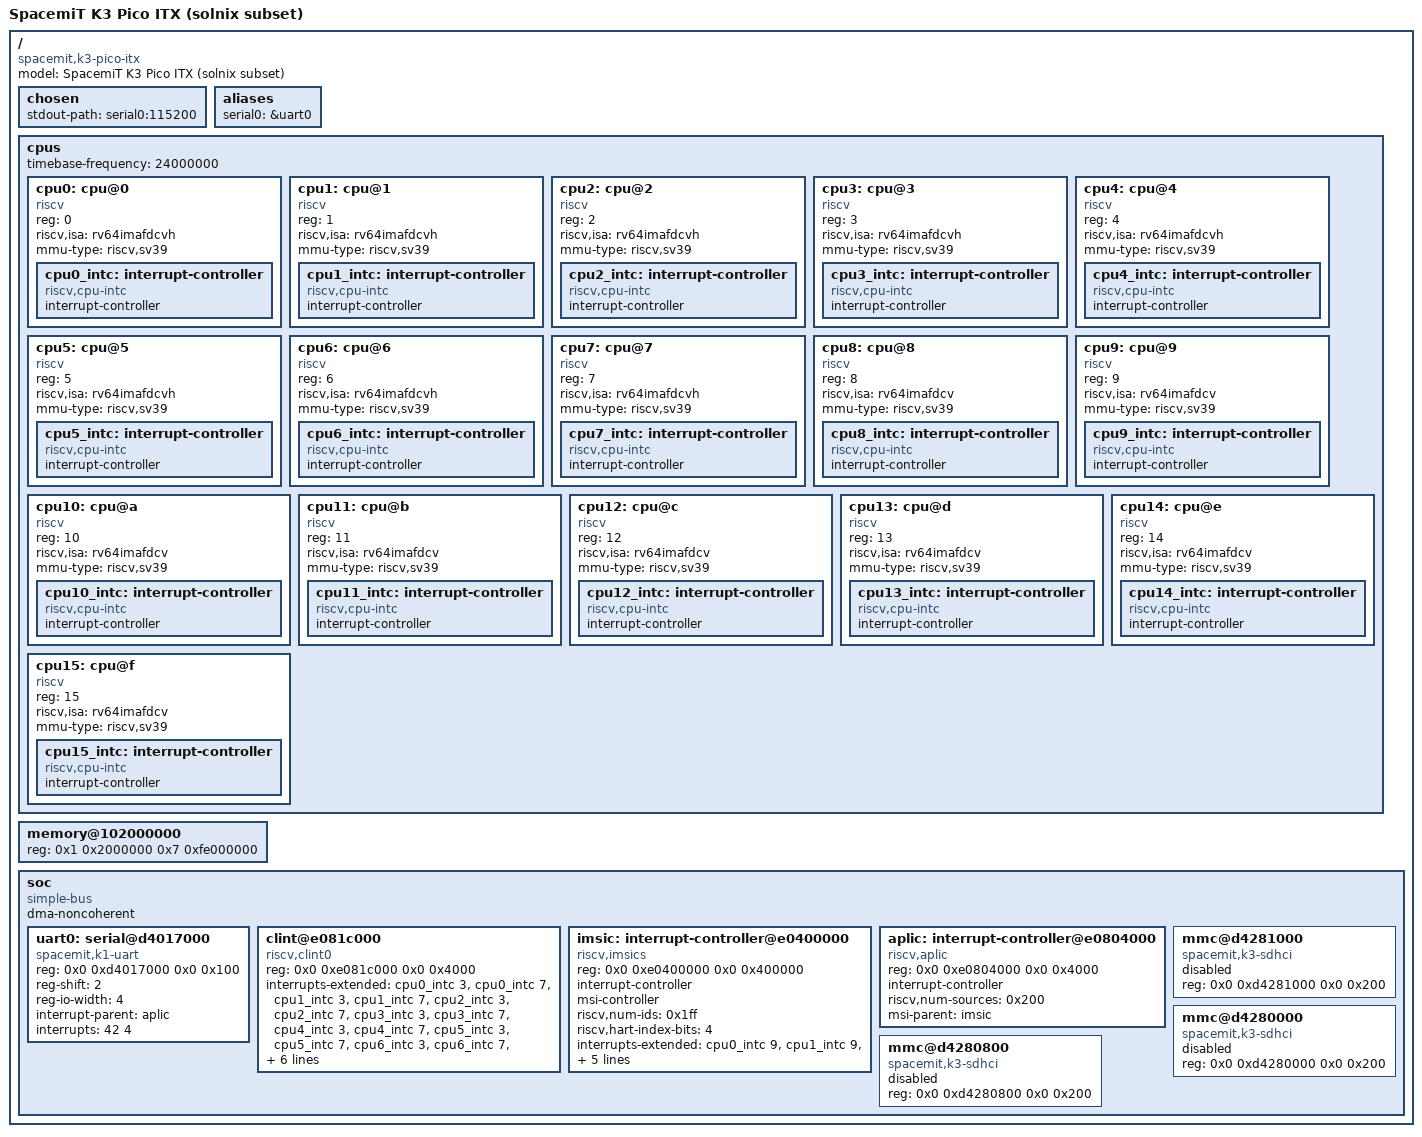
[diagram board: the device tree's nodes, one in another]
/dts-v1/;

/*
 * k3.dts - a faithful SUBSET of the SpacemiT K3 Pico ITX devicetree,
 * GENERATED by gen-k3-dts.py from the board's own vendor DTB dump.
 *
 * DO NOT HAND-EDIT. Re-run:
 *     ./gen-k3-dts.py <vendor.dts> k3.dts
 * Every boot-critical value below was EXTRACTED from the dump, and the
 * generator refuses to emit a file if the dump disagrees with what it
 * expects (16 contiguous sv39 harts, a memory node, an APLIC, and the
 * console UART at 0xd4017000 with reg-shift 2 / reg-io-width 4).
 *
 * The predecessor k1.dts was hand-written before its board existed and was
 * wrong on hart count, interrupt controller, MMC IP and UART bind string.
 * Generating removes exactly that class of error.
 *
 * Source dump : /tmp/dts
 * Board model : SpacemiT K3 Pico ITX
 *
 * MEASURED (from the dump, not inferred):
 *   DRAM         0x102000000 .. 0x900000000  (32.0 GiB)
 *                ^ note this is 32 MiB ABOVE the 4 GiB line,
 *                  so neither 0x80200000 nor a flat 4 GiB is inside DRAM.
 *   timebase     24000000 Hz  (the `time` CSR / CLINT rate)
 *   harts        16: rv64imafdcv x8; rv64imafdcvh x8
 *   console      /soc/serial@d4017000 @ 0xd4017000, serial0:115200
 *                compatible = "spacemit,k1-uart", "intel,xscale-uart"
 *                reg-shift = 2, reg-io-width = 4, IRQ 42
 *   CLINT        0xe081c000 riscv,clint0
 *   APLIC        0xe0804000 riscv,aplic, 512 sources
 *   IMSIC        0xe0400000 riscv,imsics, 511 ids, hart-index-bits 4
 *   SD/MMC       mmc@d4281000 disabled, mmc@d4280000 disabled, mmc@d4280800 disabled
 *                ^ ALL DISABLED on this board. There is no SD card path:
 *                  the boot chain lives in SPI NOR (boot_mode=nor) and the
 *                  root device is UFS. Carried through as disabled so the
 *                  kernel does not bind a controller the board does not use.
 *
 * The K3 is an AIA part (APLIC + IMSIC), so fdt_intc_is_aia() selects
 * uts/aia.c here, NOT the PLIC path uts/plic.c that qemu-virt uses.
 */

/ {
	#address-cells = <2>;
	#size-cells = <2>;
	model = "SpacemiT K3 Pico ITX (solnix subset)";
	compatible = "spacemit,k3-pico-itx";

	chosen {
		stdout-path = "serial0:115200";
	};

	aliases {
		serial0 = &uart0;
	};

	cpus {
		#address-cells = <1>;
		#size-cells = <0>;
		timebase-frequency = <24000000>;	/* measured: 24 MHz */

		/*
		 * 16 harts. SMP bring-up must handle all of them: hart 0
		 * boots and the rest come up via SBI HSM hart_start. The two ISA
		 * strings differ ONLY by the `h` (hypervisor) extension, which we do
		 * not use, and every hart is sv39 -- so this is not a big.LITTLE
		 * problem for the kernel. The COUNT is what matters.
		 */
		cpu0: cpu@0 {
			device_type = "cpu";
			compatible = "riscv";
			reg = <0>;
			riscv,isa = "rv64imafdcvh";
			mmu-type = "riscv,sv39";
			status = "okay";	/* Spacemit(R) X100 */
			cpu0_intc: interrupt-controller {
				compatible = "riscv,cpu-intc";
				#interrupt-cells = <1>;
				interrupt-controller;
			};
		};

		cpu1: cpu@1 {
			device_type = "cpu";
			compatible = "riscv";
			reg = <1>;
			riscv,isa = "rv64imafdcvh";
			mmu-type = "riscv,sv39";
			status = "okay";	/* Spacemit(R) X100 */
			cpu1_intc: interrupt-controller {
				compatible = "riscv,cpu-intc";
				#interrupt-cells = <1>;
				interrupt-controller;
			};
		};

		cpu2: cpu@2 {
			device_type = "cpu";
			compatible = "riscv";
			reg = <2>;
			riscv,isa = "rv64imafdcvh";
			mmu-type = "riscv,sv39";
			status = "okay";	/* Spacemit(R) X100 */
			cpu2_intc: interrupt-controller {
				compatible = "riscv,cpu-intc";
				#interrupt-cells = <1>;
				interrupt-controller;
			};
		};

		cpu3: cpu@3 {
			device_type = "cpu";
			compatible = "riscv";
			reg = <3>;
			riscv,isa = "rv64imafdcvh";
			mmu-type = "riscv,sv39";
			status = "okay";	/* Spacemit(R) X100 */
			cpu3_intc: interrupt-controller {
				compatible = "riscv,cpu-intc";
				#interrupt-cells = <1>;
				interrupt-controller;
			};
		};

		cpu4: cpu@4 {
			device_type = "cpu";
			compatible = "riscv";
			reg = <4>;
			riscv,isa = "rv64imafdcvh";
			mmu-type = "riscv,sv39";
			status = "okay";	/* Spacemit(R) X100 */
			cpu4_intc: interrupt-controller {
				compatible = "riscv,cpu-intc";
				#interrupt-cells = <1>;
				interrupt-controller;
			};
		};

		cpu5: cpu@5 {
			device_type = "cpu";
			compatible = "riscv";
			reg = <5>;
			riscv,isa = "rv64imafdcvh";
			mmu-type = "riscv,sv39";
			status = "okay";	/* Spacemit(R) X100 */
			cpu5_intc: interrupt-controller {
				compatible = "riscv,cpu-intc";
				#interrupt-cells = <1>;
				interrupt-controller;
			};
		};

		cpu6: cpu@6 {
			device_type = "cpu";
			compatible = "riscv";
			reg = <6>;
			riscv,isa = "rv64imafdcvh";
			mmu-type = "riscv,sv39";
			status = "okay";	/* Spacemit(R) X100 */
			cpu6_intc: interrupt-controller {
				compatible = "riscv,cpu-intc";
				#interrupt-cells = <1>;
				interrupt-controller;
			};
		};

		cpu7: cpu@7 {
			device_type = "cpu";
			compatible = "riscv";
			reg = <7>;
			riscv,isa = "rv64imafdcvh";
			mmu-type = "riscv,sv39";
			status = "okay";	/* Spacemit(R) X100 */
			cpu7_intc: interrupt-controller {
				compatible = "riscv,cpu-intc";
				#interrupt-cells = <1>;
				interrupt-controller;
			};
		};

		cpu8: cpu@8 {
			device_type = "cpu";
			compatible = "riscv";
			reg = <8>;
			riscv,isa = "rv64imafdcv";
			mmu-type = "riscv,sv39";
			status = "okay";	/* Spacemit(R) A100 */
			cpu8_intc: interrupt-controller {
				compatible = "riscv,cpu-intc";
				#interrupt-cells = <1>;
				interrupt-controller;
			};
		};

		cpu9: cpu@9 {
			device_type = "cpu";
			compatible = "riscv";
			reg = <9>;
			riscv,isa = "rv64imafdcv";
			mmu-type = "riscv,sv39";
			status = "okay";	/* Spacemit(R) A100 */
			cpu9_intc: interrupt-controller {
				compatible = "riscv,cpu-intc";
				#interrupt-cells = <1>;
				interrupt-controller;
			};
		};

		cpu10: cpu@a {
			device_type = "cpu";
			compatible = "riscv";
			reg = <10>;
			riscv,isa = "rv64imafdcv";
			mmu-type = "riscv,sv39";
			status = "okay";	/* Spacemit(R) A100 */
			cpu10_intc: interrupt-controller {
				compatible = "riscv,cpu-intc";
				#interrupt-cells = <1>;
				interrupt-controller;
			};
		};

		cpu11: cpu@b {
			device_type = "cpu";
			compatible = "riscv";
			reg = <11>;
			riscv,isa = "rv64imafdcv";
			mmu-type = "riscv,sv39";
			status = "okay";	/* Spacemit(R) A100 */
			cpu11_intc: interrupt-controller {
				compatible = "riscv,cpu-intc";
				#interrupt-cells = <1>;
				interrupt-controller;
			};
		};

		cpu12: cpu@c {
			device_type = "cpu";
			compatible = "riscv";
			reg = <12>;
			riscv,isa = "rv64imafdcv";
			mmu-type = "riscv,sv39";
			status = "okay";	/* Spacemit(R) A100 */
			cpu12_intc: interrupt-controller {
				compatible = "riscv,cpu-intc";
				#interrupt-cells = <1>;
				interrupt-controller;
			};
		};

		cpu13: cpu@d {
			device_type = "cpu";
			compatible = "riscv";
			reg = <13>;
			riscv,isa = "rv64imafdcv";
			mmu-type = "riscv,sv39";
			status = "okay";	/* Spacemit(R) A100 */
			cpu13_intc: interrupt-controller {
				compatible = "riscv,cpu-intc";
				#interrupt-cells = <1>;
				interrupt-controller;
			};
		};

		cpu14: cpu@e {
			device_type = "cpu";
			compatible = "riscv";
			reg = <14>;
			riscv,isa = "rv64imafdcv";
			mmu-type = "riscv,sv39";
			status = "okay";	/* Spacemit(R) A100 */
			cpu14_intc: interrupt-controller {
				compatible = "riscv,cpu-intc";
				#interrupt-cells = <1>;
				interrupt-controller;
			};
		};

		cpu15: cpu@f {
			device_type = "cpu";
			compatible = "riscv";
			reg = <15>;
			riscv,isa = "rv64imafdcv";
			mmu-type = "riscv,sv39";
			status = "okay";	/* Spacemit(R) A100 */
			cpu15_intc: interrupt-controller {
				compatible = "riscv,cpu-intc";
				#interrupt-cells = <1>;
				interrupt-controller;
			};
		};

	};

	memory@102000000 {
		device_type = "memory";
		reg = <0x1 0x2000000 0x7 0xfe000000>;
	};

	soc {
		compatible = "simple-bus";
		#address-cells = <2>;
		#size-cells = <2>;
		ranges;
		dma-noncoherent;

		uart0: serial@d4017000 {
			compatible = "spacemit,k1-uart", "intel,xscale-uart";
			reg = <0x0 0xd4017000 0x0 0x100>;
			reg-shift = <2>;
			reg-io-width = <4>;
			interrupt-parent = <&aplic>;
			interrupts = <42 4>;
			status = "okay";
		};

		clint@e081c000 {
			compatible = "riscv,clint0";
			reg = <0x0 0xe081c000 0x0 0x4000>;
			interrupts-extended = <&cpu0_intc 3 &cpu0_intc 7 &cpu1_intc 3 &cpu1_intc 7 &cpu2_intc 3 &cpu2_intc 7 &cpu3_intc 3 &cpu3_intc 7
			    &cpu4_intc 3 &cpu4_intc 7 &cpu5_intc 3 &cpu5_intc 7 &cpu6_intc 3 &cpu6_intc 7 &cpu7_intc 3 &cpu7_intc 7
			    &cpu8_intc 3 &cpu8_intc 7 &cpu9_intc 3 &cpu9_intc 7 &cpu10_intc 3 &cpu10_intc 7 &cpu11_intc 3 &cpu11_intc 7
			    &cpu12_intc 3 &cpu12_intc 7 &cpu13_intc 3 &cpu13_intc 7 &cpu14_intc 3 &cpu14_intc 7 &cpu15_intc 3 &cpu15_intc 7>;
		};

		imsic: interrupt-controller@e0400000 {
			compatible = "riscv,imsics";
			reg = <0x0 0xe0400000 0x0 0x400000>;
			interrupt-controller;
			msi-controller;
			#interrupt-cells = <0>;
			#msi-cells = <0>;
			riscv,num-ids = <0x1ff>;
			riscv,hart-index-bits = <4>;
			interrupts-extended = <&cpu0_intc 9 &cpu1_intc 9 &cpu2_intc 9 &cpu3_intc 9 &cpu4_intc 9 &cpu5_intc 9 &cpu6_intc 9 &cpu7_intc 9
			    &cpu8_intc 9 &cpu9_intc 9 &cpu10_intc 9 &cpu11_intc 9 &cpu12_intc 9 &cpu13_intc 9 &cpu14_intc 9 &cpu15_intc 9>;
			status = "okay";
		};

		aplic: interrupt-controller@e0804000 {
			compatible = "riscv,aplic";
			reg = <0x0 0xe0804000 0x0 0x4000>;
			interrupt-controller;
			#interrupt-cells = <2>;
			riscv,num-sources = <0x200>;
			msi-parent = <&imsic>;
			status = "okay";
		};

		mmc@d4281000 {
			compatible = "spacemit,k3-sdhci";
			reg = <0x0 0xd4281000 0x0 0x200>;
			status = "disabled";	/* as measured on the board */
		};

		mmc@d4280000 {
			compatible = "spacemit,k3-sdhci";
			reg = <0x0 0xd4280000 0x0 0x200>;
			status = "disabled";	/* as measured on the board */
		};

		mmc@d4280800 {
			compatible = "spacemit,k3-sdhci";
			reg = <0x0 0xd4280800 0x0 0x200>;
			status = "disabled";	/* as measured on the board */
		};

	};
};
